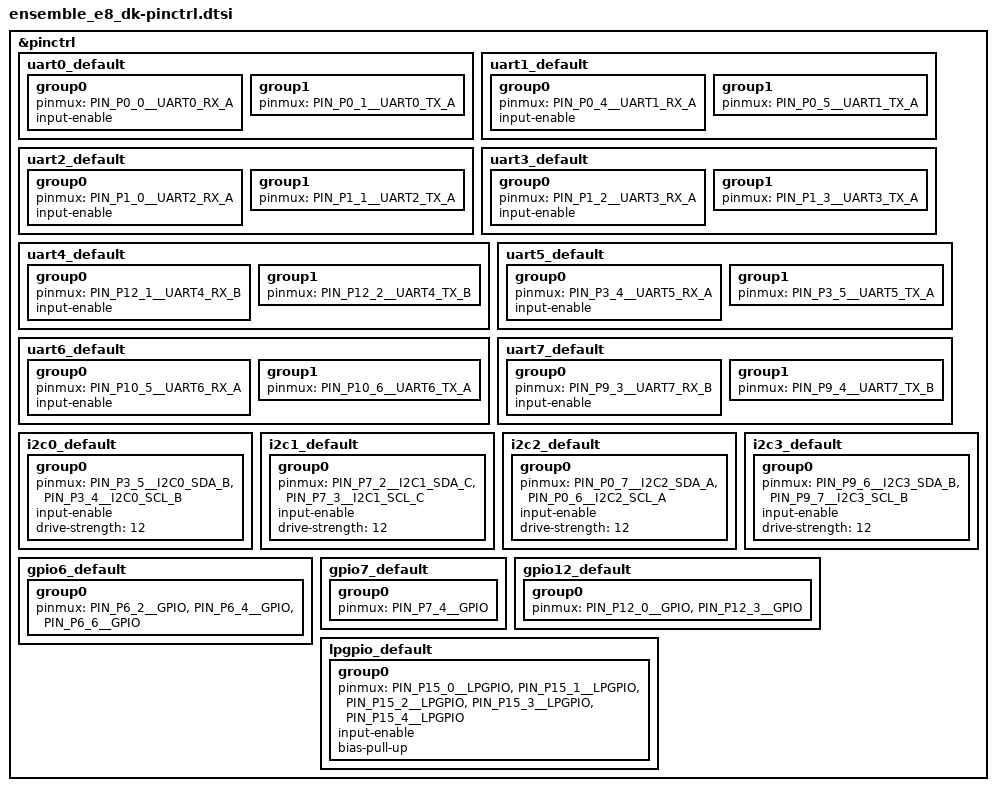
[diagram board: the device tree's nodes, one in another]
/*
 * Copyright (c) 2025 Alif Semiconductor
 *
 * SPDX-License-Identifier: Apache-2.0
 */

#include <zephyr/dt-bindings/pinctrl/alif-ensemble-pinctrl.h>

&pinctrl {
	uart0_default: uart0_default {
		group0 {
			pinmux = <PIN_P0_0__UART0_RX_A>;
			input-enable;
		};

		group1 {
			pinmux = <PIN_P0_1__UART0_TX_A>;
		};
	};

	uart1_default: uart1_default {
		group0 {
			pinmux = <PIN_P0_4__UART1_RX_A>;
			input-enable;
		};

		group1 {
			pinmux = <PIN_P0_5__UART1_TX_A>;
		};
	};

	uart2_default: uart2_default {
		group0 {
			pinmux = <PIN_P1_0__UART2_RX_A>;
			input-enable;
		};

		group1 {
			pinmux = <PIN_P1_1__UART2_TX_A>;
		};
	};

	uart3_default: uart3_default {
		group0 {
			pinmux = <PIN_P1_2__UART3_RX_A>;
			input-enable;
		};

		group1 {
			pinmux = <PIN_P1_3__UART3_TX_A>;
		};
	};

	uart4_default: uart4_default {
		group0 {
			pinmux = <PIN_P12_1__UART4_RX_B>;
			input-enable;
		};

		group1 {
			pinmux = <PIN_P12_2__UART4_TX_B>;
		};
	};

	uart5_default: uart5_default {
		group0 {
			pinmux = <PIN_P3_4__UART5_RX_A>;
			input-enable;
		};

		group1 {
			pinmux = <PIN_P3_5__UART5_TX_A>;
		};
	};

	uart6_default: uart6_default {
		group0 {
			pinmux = <PIN_P10_5__UART6_RX_A>;
			input-enable;
		};

		group1 {
			pinmux = <PIN_P10_6__UART6_TX_A>;
		};
	};

	uart7_default: uart7_default {
		group0 {
			pinmux = <PIN_P9_3__UART7_RX_B>;
			input-enable;
		};

		group1 {
			pinmux = <PIN_P9_4__UART7_TX_B>;
		};
	};

	i2c0_default: i2c0_default {
		group0 {
			pinmux = <PIN_P3_5__I2C0_SDA_B>,
				 <PIN_P3_4__I2C0_SCL_B>;
			input-enable;
			drive-strength = <12>;
		};
	};

	i2c1_default: i2c1_default {
		group0 {
			pinmux = <PIN_P7_2__I2C1_SDA_C>,
				 <PIN_P7_3__I2C1_SCL_C>;
			input-enable;
			drive-strength = <12>;
		};
	};

	i2c2_default: i2c2_default {
		group0 {
			pinmux = <PIN_P0_7__I2C2_SDA_A>,
				 <PIN_P0_6__I2C2_SCL_A>;
			input-enable;
			drive-strength = <12>;
		};
	};

	i2c3_default: i2c3_default {
		group0 {
			pinmux = <PIN_P9_6__I2C3_SDA_B>,
				 <PIN_P9_7__I2C3_SCL_B>;
			input-enable;
			drive-strength = <12>;
		};
	};

	gpio6_default: gpio6_default {
		group0 {
			/* Multicolor LED1: red on P6_2, green on P6_4, blue on P6_6 */
			pinmux = <PIN_P6_2__GPIO>,
				 <PIN_P6_4__GPIO>,
				 <PIN_P6_6__GPIO>;
		};
	};

	gpio7_default: gpio7_default {
		group0 {
			/* Multicolor LED0: green on P7_4 */
			pinmux = <PIN_P7_4__GPIO>;
		};
	};

	gpio12_default: gpio12_default {
		group0 {
			/* Multicolor LED0: blue on P12_0, red on P12_3 */
			pinmux = <PIN_P12_0__GPIO>,
				 <PIN_P12_3__GPIO>;
		};
	};

	lpgpio_default: lpgpio_default {
		group0 {
			/* Navigation joystick JOY_SW1 to JOY_SW5 on SW2 */
			pinmux = <PIN_P15_0__LPGPIO>,
				 <PIN_P15_1__LPGPIO>,
				 <PIN_P15_2__LPGPIO>,
				 <PIN_P15_3__LPGPIO>,
				 <PIN_P15_4__LPGPIO>;
			input-enable;
			bias-pull-up;
		};
	};
};
